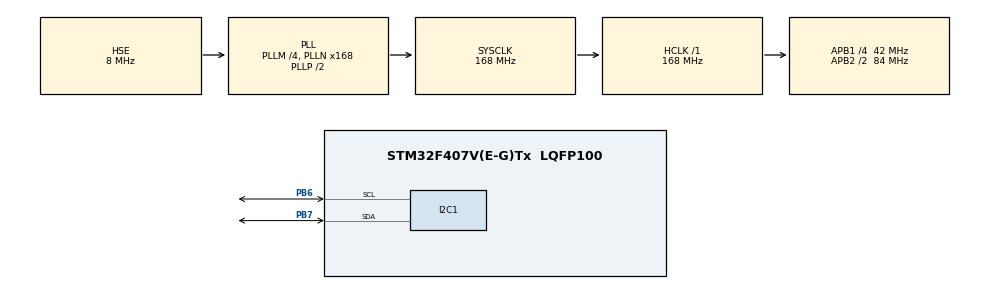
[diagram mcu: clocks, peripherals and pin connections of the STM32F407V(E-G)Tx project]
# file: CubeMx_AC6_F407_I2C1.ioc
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Mcu.Family=STM32F4
Mcu.Name=STM32F407V(E-G)Tx
Mcu.Package=LQFP100
NVIC.PriorityGroup=NVIC_PRIORITYGROUP_4
PB6.Mode=I2C
PB6.Signal=I2C1_SCL
PB7.Mode=I2C
PB7.Signal=I2C1_SDA
PH0-OSC_IN.Mode=HSE-External-Oscillator
PH0-OSC_IN.Signal=RCC_OSC_IN
PH1-OSC_OUT.Mode=HSE-External-Oscillator
PH1-OSC_OUT.Signal=RCC_OSC_OUT
ProjectManager.HeapSize=0x200
ProjectManager.StackSize=0x400
ProjectManager.TargetToolchain=SW4STM32
RCC.48MHZClocksFreq_Value=84000000
RCC.AHBFreq_Value=168000000
RCC.APB1CLKDivider=RCC_HCLK_DIV4
RCC.APB1Freq_Value=42000000
RCC.APB1TimFreq_Value=84000000
RCC.APB2CLKDivider=RCC_HCLK_DIV2
RCC.APB2Freq_Value=84000000
RCC.APB2TimFreq_Value=168000000
RCC.CortexFreq_Value=168000000
RCC.HCLKFreq_Value=168000000
RCC.HSE_VALUE=8000000
RCC.HSI_VALUE=16000000
RCC.LSE_VALUE=32768
RCC.PLLM=4
RCC.PLLN=168
RCC.PLLSourceVirtual=RCC_PLLSOURCE_HSE
RCC.SYSCLKFreq_VALUE=168000000
RCC.SYSCLKSource=RCC_SYSCLKSOURCE_PLLCLK
RCC.VCOOutputFreq_Value=336000000
board=CubeMx_AC6_F407_I2C1

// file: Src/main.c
/**
  ******************************************************************************
  * File Name          : main.c
  * Description        : Main program body
  ******************************************************************************
  *
  * COPYRIGHT(c) 2017 STMicroelectronics
  *
  * Redistribution and use in source and binary forms, with or without modification,
  * are permitted provided that the following conditions are met:
  *   1. Redistributions of source code must retain the above copyright notice,
  *      this list of conditions and the following disclaimer.
  *   2. Redistributions in binary form must reproduce the above copyright notice,
  *      this list of conditions and the following disclaimer in the documentation
  *      and/or other materials provided with the distribution.
  *   3. Neither the name of STMicroelectronics nor the names of its contributors
  *      may be used to endorse or promote products derived from this software
  *      without specific prior written permission.
  *
  * THIS SOFTWARE IS PROVIDED BY THE COPYRIGHT HOLDERS AND CONTRIBUTORS "AS IS"
  * AND ANY EXPRESS OR IMPLIED WARRANTIES, INCLUDING, BUT NOT LIMITED TO, THE
  * IMPLIED WARRANTIES OF MERCHANTABILITY AND FITNESS FOR A PARTICULAR PURPOSE ARE
  * DISCLAIMED. IN NO EVENT SHALL THE COPYRIGHT HOLDER OR CONTRIBUTORS BE LIABLE
  * FOR ANY DIRECT, INDIRECT, INCIDENTAL, SPECIAL, EXEMPLARY, OR CONSEQUENTIAL
  * DAMAGES (INCLUDING, BUT NOT LIMITED TO, PROCUREMENT OF SUBSTITUTE GOODS OR
  * SERVICES; LOSS OF USE, DATA, OR PROFITS; OR BUSINESS INTERRUPTION) HOWEVER
  * CAUSED AND ON ANY THEORY OF LIABILITY, WHETHER IN CONTRACT, STRICT LIABILITY,
  * OR TORT (INCLUDING NEGLIGENCE OR OTHERWISE) ARISING IN ANY WAY OUT OF THE USE
  * OF THIS SOFTWARE, EVEN IF ADVISED OF THE POSSIBILITY OF SUCH DAMAGE.
  *
  ******************************************************************************
  */
#include "main.h"
#include "stm32f4xx_hal.h"

I2C_HandleTypeDef hi2c1;

/* USER CODE BEGIN PV */
/* Private variables ---------------------------------------------------------*/

/* USER CODE END PV */

void SystemClock_Config(void);
void Error_Handler(void);
static void MX_GPIO_Init(void);
static void MX_I2C1_Init(void);

/* USER CODE BEGIN PFP */
/* Private function prototypes -----------------------------------------------*/

/* USER CODE END PFP */

/* USER CODE BEGIN 0 */
#define SLAVE_ADRESS 0xD0

uint8_t Second,Minute,Hour;
uint8_t data[2];
/* USER CODE END 0 */

int main(void)
{

  /* MCU Configuration----------------------------------------------------------*/

  /* Reset of all peripherals, Initializes the Flash interface and the Systick. */
  HAL_Init();

  /* Configure the system clock */
  SystemClock_Config();

  /* Initialize all configured peripherals */
  MX_GPIO_Init();
  MX_I2C1_Init();

  /* USER CODE BEGIN 2 */
  data[0]=0x00;
  data[1]=0xFF;
  /* USER CODE END 2 */

  /* Infinite loop */
  /* USER CODE BEGIN WHILE */
  while (1)
  {

	  //HAL_StatusTypeDef HAL_I2C_Master_Transmit(I2C_HandleTypeDef *hi2c, uint16_t DevAddress,
	  //uint8_t *pData, uint16_t Size, uint32_t Timeout);

	  data[0]=0x00;
	  HAL_I2C_Master_Transmit(&hi2c1,SLAVE_ADRESS,data,1,50);
	  HAL_I2C_Master_Receive(&hi2c1,0xD0|0x01,&Second,1,50);

	  data[0]=0x01;
	  HAL_I2C_Master_Transmit(&hi2c1,SLAVE_ADRESS,data,1,50);
	  HAL_I2C_Master_Receive(&hi2c1,0xD0 |0x01,&Minute,1,50);

	  data[0]=0x02;
	  HAL_I2C_Master_Transmit(&hi2c1,SLAVE_ADRESS,data,1,50);
	  HAL_I2C_Master_Receive(&hi2c1,0xD0 |0x01,&Hour,1,50);

  /* USER CODE END WHILE */

  }

}

/** System Clock Configuration
*/
void SystemClock_Config(void)
{

  RCC_OscInitTypeDef RCC_OscInitStruct;
  RCC_ClkInitTypeDef RCC_ClkInitStruct;

    /**Configure the main internal regulator output voltage
    */
  __HAL_RCC_PWR_CLK_ENABLE();

  __HAL_PWR_VOLTAGESCALING_CONFIG(PWR_REGULATOR_VOLTAGE_SCALE1);

    /**Initializes the CPU, AHB and APB busses clocks
    */
  RCC_OscInitStruct.OscillatorType = RCC_OSCILLATORTYPE_HSE;
  RCC_OscInitStruct.HSEState = RCC_HSE_ON;
  RCC_OscInitStruct.PLL.PLLState = RCC_PLL_ON;
  RCC_OscInitStruct.PLL.PLLSource = RCC_PLLSOURCE_HSE;
  RCC_OscInitStruct.PLL.PLLM = 4;
  RCC_OscInitStruct.PLL.PLLN = 168;
  RCC_OscInitStruct.PLL.PLLP = RCC_PLLP_DIV2;
  RCC_OscInitStruct.PLL.PLLQ = 4;
  if (HAL_RCC_OscConfig(&RCC_OscInitStruct) != HAL_OK)
  {
    Error_Handler();
  }

    /**Initializes the CPU, AHB and APB busses clocks
    */
  RCC_ClkInitStruct.ClockType = RCC_CLOCKTYPE_HCLK|RCC_CLOCKTYPE_SYSCLK
                              |RCC_CLOCKTYPE_PCLK1|RCC_CLOCKTYPE_PCLK2;
  RCC_ClkInitStruct.SYSCLKSource = RCC_SYSCLKSOURCE_PLLCLK;
  RCC_ClkInitStruct.AHBCLKDivider = RCC_SYSCLK_DIV1;
  RCC_ClkInitStruct.APB1CLKDivider = RCC_HCLK_DIV4;
  RCC_ClkInitStruct.APB2CLKDivider = RCC_HCLK_DIV2;

  if (HAL_RCC_ClockConfig(&RCC_ClkInitStruct, FLASH_LATENCY_5) != HAL_OK)
  {
    Error_Handler();
  }

    /**Configure the Systick interrupt time
    */
  HAL_SYSTICK_Config(HAL_RCC_GetHCLKFreq()/1000);

    /**Configure the Systick
    */
  HAL_SYSTICK_CLKSourceConfig(SYSTICK_CLKSOURCE_HCLK);

  /* SysTick_IRQn interrupt configuration */
  HAL_NVIC_SetPriority(SysTick_IRQn, 0, 0);
}

/* I2C1 init function */
static void MX_I2C1_Init(void)
{

  hi2c1.Instance = I2C1;
  hi2c1.Init.ClockSpeed = 100000;
  hi2c1.Init.DutyCycle = I2C_DUTYCYCLE_2;
  hi2c1.Init.OwnAddress1 = 0;
  hi2c1.Init.AddressingMode = I2C_ADDRESSINGMODE_7BIT;
  hi2c1.Init.DualAddressMode = I2C_DUALADDRESS_DISABLE;
  hi2c1.Init.OwnAddress2 = 0;
  hi2c1.Init.GeneralCallMode = I2C_GENERALCALL_DISABLE;
  hi2c1.Init.NoStretchMode = I2C_NOSTRETCH_DISABLE;
  if (HAL_I2C_Init(&hi2c1) != HAL_OK)
  {
    Error_Handler();
  }

}

/** Configure pins as
        * Analog
        * Input
        * Output
        * EVENT_OUT
        * EXTI
*/
static void MX_GPIO_Init(void)
{

  /* GPIO Ports Clock Enable */
  __HAL_RCC_GPIOH_CLK_ENABLE();
  __HAL_RCC_GPIOB_CLK_ENABLE();

}

void Error_Handler(void)
{
  while(1)
  {
  }
}

/************************ (C) COPYRIGHT STMicroelectronics *****END OF FILE****/
